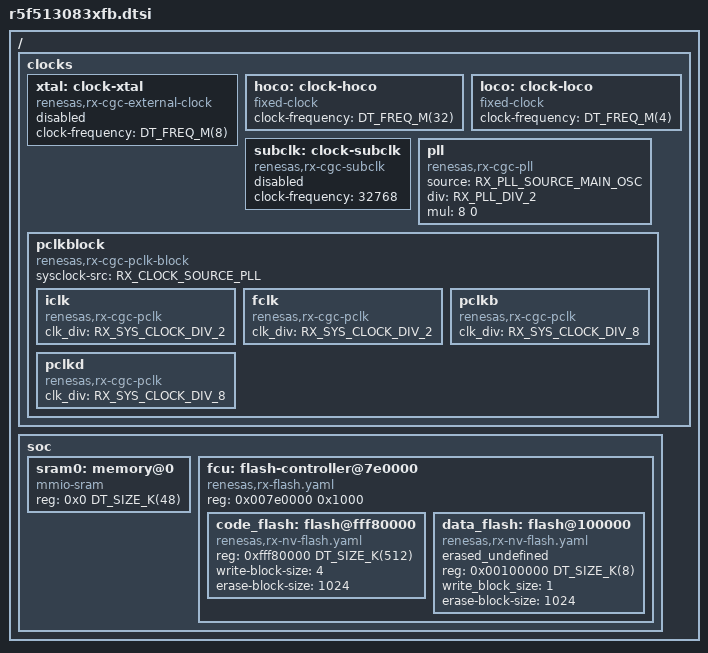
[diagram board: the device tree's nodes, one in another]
/*
 * Copyright (c) 2024 Renesas Electronics Corporation
 *
 * SPDX-License-Identifier: Apache-2.0
 */
#include <rx/renesas/rx130-common.dtsi>
#include <freq.h>
#include <zephyr/dt-bindings/clock/rx_clock.h>

/ {
	clocks: clocks {
		xtal: clock-xtal {
			compatible = "renesas,rx-cgc-external-clock";
			clock-frequency = <DT_FREQ_M(8)>;
			#clock-cells = <0>;
			status = "disabled";
		};

		hoco: clock-hoco {
			compatible = "fixed-clock";
			clock-frequency = <DT_FREQ_M(32)>;
			#clock-cells = <0>;
			status = "okay";
		};

		loco: clock-loco {
			compatible = "fixed-clock";
			clock-frequency =  <DT_FREQ_M(4)>;
			#clock-cells = <0>;
			status = "okay";
		};

		subclk: clock-subclk {
			compatible = "renesas,rx-cgc-subclk";
			clock-frequency = <32768>;
			#clock-cells = <0>;
			status = "disabled";
		};

		pll: pll {
			compatible = "renesas,rx-cgc-pll";
			#clock-cells = <0>;

			/* PLL */
			source = <RX_PLL_SOURCE_MAIN_OSC>;
			div = <RX_PLL_DIV_2>;
			mul = <8 0>;
		};

		pclkblock: pclkblock {
			compatible = "renesas,rx-cgc-pclk-block";
			#clock-cells = <0>;
			sysclock-src = <RX_CLOCK_SOURCE_PLL>;
			status = "okay";

			iclk: iclk {
				compatible = "renesas,rx-cgc-pclk";
				clk_div = <RX_SYS_CLOCK_DIV_2>;
				#clock-cells = <2>;
				status = "okay";
			};

			fclk: fclk {
				compatible = "renesas,rx-cgc-pclk";
				clk_div = <RX_SYS_CLOCK_DIV_2>;
				#clock-cells = <2>;
				status = "okay";
			};

			pclkb: pclkb {
				compatible = "renesas,rx-cgc-pclk";
				clk_div = <RX_SYS_CLOCK_DIV_8>;
				#clock-cells = <2>;
				status = "okay";
			};

			pclkd: pclkd {
				compatible = "renesas,rx-cgc-pclk";
				clk_div = <RX_SYS_CLOCK_DIV_8>;
				#clock-cells = <2>;
				status = "okay";
			};
		};
	};

	soc {
		sram0: memory@0 {
			device_type = "memory";
			compatible = "mmio-sram";
			reg = <0x0 DT_SIZE_K(48)>;
		};

		fcu: flash-controller@7e0000 {
			#address-cells = <1>;
			#size-cells = <1>;
			compatible = "renesas,rx-flash.yaml";
			reg = <0x007e0000 0x1000>;

			code_flash: flash@fff80000 {
				compatible = "renesas,rx-nv-flash.yaml";
				reg = <0xfff80000 DT_SIZE_K(512)>;
				write-block-size = <4>;
				erase-block-size = <1024>;
			};

			data_flash: flash@100000 {
				compatible = "renesas,rx-nv-flash.yaml";
				erased_undefined;
				reg = <0x00100000 DT_SIZE_K(8)>;
				write_block_size = <1>;
				erase-block-size = <1024>;
			};
		};
	};
};
